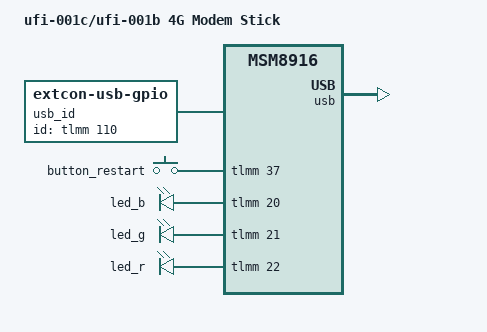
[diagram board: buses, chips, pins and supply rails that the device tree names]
// SPDX-License-Identifier: GPL-2.0-only

/dts-v1/;

#include "msm8916-ufi.dtsi"

/ {
	model = "ufi-001c/ufi-001b 4G Modem Stick";
	compatible = "thwc,ufi001c", "qcom,msm8916";

	usb_id: usb-id {
		compatible = "linux,extcon-usb-gpio";
		id-gpios = <&tlmm 110 GPIO_ACTIVE_HIGH>;
		pinctrl-0 = <&usb_id_default>;
		pinctrl-names = "default";
	};
};

&button_restart {
	gpios = <&tlmm 37 GPIO_ACTIVE_HIGH>;
};

&led_b {
	gpios = <&tlmm 20 GPIO_ACTIVE_HIGH>;
};

&led_g {
	gpios = <&tlmm 21 GPIO_ACTIVE_HIGH>;
};

&led_r {
	gpios = <&tlmm 22 GPIO_ACTIVE_HIGH>;
};

&mpss {
	pinctrl-0 = <&sim_ctrl_default>;
	pinctrl-names = "default";
};

&usb {
	extcon = <&usb_id>, <&usb_id>;

	status = "okay";
};

&usb_hs_phy {
	extcon = <&usb_id>;
};

&button_default {
	pins = "gpio37";
	bias-pull-down;
};

&gpio_leds_default {
	pins = "gpio20", "gpio21", "gpio22";
};

/* This selects the external SIM card slot by default */
&tlmm {
	sim_ctrl_default: sim-ctrl-default-state {
		esim-sel-pins {
			pins = "gpio0", "gpio3";
			function = "gpio";
			bias-disable;
			output-low;
		};

		sim-en-pins {
			pins = "gpio1";
			function = "gpio";
			bias-disable;
			output-low;
		};

		sim-sel-pins {
			pins = "gpio2";
			function = "gpio";
			bias-disable;
			output-high;
		};
	};

	usb_id_default: usb-id-default-state {
		pins = "gpio109";
		function = "gpio";
		drive-strength = <8>;
		bias-pull-up;
	};
};
